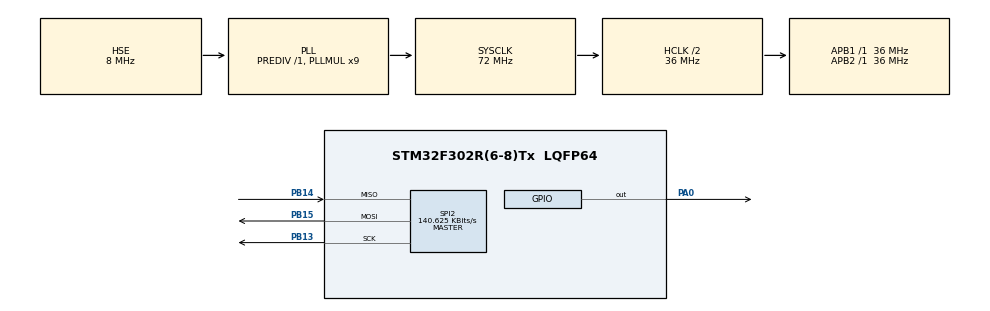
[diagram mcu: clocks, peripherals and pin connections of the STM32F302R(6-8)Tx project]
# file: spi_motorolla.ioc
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Mcu.Family=STM32F3
Mcu.Name=STM32F302R(6-8)Tx
Mcu.Package=LQFP64
NVIC.PriorityGroup=NVIC_PRIORITYGROUP_0
PA0.GPIO_Speed=GPIO_SPEED_FREQ_HIGH
PA0.Signal=GPIO_Output
PA13.GPIO_Label=TMS
PA13.Mode=Serial_Wire
PA13.Signal=SYS_JTMS-SWDIO
PA14.GPIO_Label=TCK
PA14.Mode=Serial_Wire
PA14.Signal=SYS_JTCK-SWCLK
PB13.Mode=Full_Duplex_Master
PB13.Signal=SPI2_SCK
PB14.Mode=Full_Duplex_Master
PB14.Signal=SPI2_MISO
PB15.Mode=Full_Duplex_Master
PB15.Signal=SPI2_MOSI
PC14\ -\ OSC32_IN.Mode=LSE-External-Clock-Source
PC14\ -\ OSC32_IN.Signal=RCC_OSC32_IN
PF0-OSC_IN.Mode=HSE-External-Oscillator
PF0-OSC_IN.Signal=RCC_OSC_IN
PF1-OSC_OUT.Mode=HSE-External-Oscillator
PF1-OSC_OUT.Signal=RCC_OSC_OUT
ProjectManager.HeapSize=0x200
ProjectManager.StackSize=0x400
ProjectManager.TargetToolchain=STM32CubeIDE
RCC.AHBCLKDivider=RCC_SYSCLK_DIV2
RCC.AHBFreq_Value=36000000
RCC.APB1Freq_Value=36000000
RCC.APB1TimFreq_Value=36000000
RCC.APB2Freq_Value=36000000
RCC.APB2TimFreq_Value=36000000
RCC.CortexFreq_Value=36000000
RCC.HCLKFreq_Value=36000000
RCC.HSE_VALUE=8000000
RCC.HSI_VALUE=8000000
RCC.LSE_VALUE=32768
RCC.PLLM=8
RCC.PLLMUL=RCC_PLL_MUL9
RCC.PLLN=336
RCC.PLLP=RCC_PLLP_DIV4
RCC.PLLQ=7
RCC.PLLSourceVirtual=RCC_PLLSOURCE_HSE
RCC.SYSCLKFreq_VALUE=72000000
RCC.SYSCLKSourceVirtual=RCC_SYSCLKSOURCE_PLLCLK
RCC.USBFreq_Value=72000000
SPI2.BaudRatePrescaler=SPI_BAUDRATEPRESCALER_256
SPI2.CalculateBaudRate=140.625 KBits/s
SPI2.DataSize=SPI_DATASIZE_8BIT
SPI2.Direction=SPI_DIRECTION_2LINES
SPI2.Mode=SPI_MODE_MASTER
SPI2.VirtualType=VM_MASTER
board=NUCLEO-F302R8

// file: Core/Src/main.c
/* USER CODE BEGIN Header */
/**
  ******************************************************************************
  * @file           : main.c
  * @brief          : Main program body
  ******************************************************************************
  * @attention
  *
  * Copyright (c) 2026 STMicroelectronics.
  * All rights reserved.
  *
  * This software is licensed under terms that can be found in the LICENSE file
  * in the root directory of this software component.
  * If no LICENSE file comes with this software, it is provided AS-IS.
  *
  ******************************************************************************
  */
/* USER CODE END Header */
#include "main.h"
#include "spi.h"
#include "gpio.h"

/* USER CODE BEGIN PV */

//uint8_t tx_Data[] = {0x11};

uint8_t tx_Data[] = {0x11, 0x22};
uint8_t rx_Data[2];
/* USER CODE END PV */

void SystemClock_Config(void);

int main(void)
{

  /* MCU Configuration--------------------------------------------------------*/

  /* Reset of all peripherals, Initializes the Flash interface and the Systick. */
  HAL_Init();

  /* Configure the system clock */
  SystemClock_Config();

  /* Initialize all configured peripherals */
  MX_GPIO_Init();
  MX_SPI2_Init();

  /* Infinite loop */
  while (1)
  {

    /* USER CODE BEGIN 3 */
	/* HAL_GPIO_WritePin(GPIOA, GPIO_PIN_0, RESET);
	HAL_SPI_Transmit(&hspi2, tx_Data, sizeof(tx_Data), HAL_MAX_DELAY);
	HAL_GPIO_WritePin(GPIOA, GPIO_PIN_0, SET);
	HAL_Delay(1000); */

    HAL_GPIO_WritePin(GPIOA, GPIO_PIN_4, RESET);
    HAL_SPI_TransmitReceive(&hspi2, tx_Data, rx_Data, sizeof(tx_Data), HAL_MAX_DELAY);
	HAL_GPIO_WritePin(GPIOA, GPIO_PIN_4, SET);
	HAL_Delay(1000);
  }
  /* USER CODE END 3 */
}

void SystemClock_Config(void)
{
  RCC_OscInitTypeDef RCC_OscInitStruct = {0};
  RCC_ClkInitTypeDef RCC_ClkInitStruct = {0};

  /** Initializes the RCC Oscillators according to the specified parameters
  * in the RCC_OscInitTypeDef structure.
  */
  RCC_OscInitStruct.OscillatorType = RCC_OSCILLATORTYPE_HSE;
  RCC_OscInitStruct.HSEState = RCC_HSE_ON;
  RCC_OscInitStruct.HSEPredivValue = RCC_HSE_PREDIV_DIV1;
  RCC_OscInitStruct.HSIState = RCC_HSI_ON;
  RCC_OscInitStruct.PLL.PLLState = RCC_PLL_ON;
  RCC_OscInitStruct.PLL.PLLSource = RCC_PLLSOURCE_HSE;
  RCC_OscInitStruct.PLL.PLLMUL = RCC_PLL_MUL9;
  if (HAL_RCC_OscConfig(&RCC_OscInitStruct) != HAL_OK)
  {
    Error_Handler();
  }

  /** Initializes the CPU, AHB and APB buses clocks
  */
  RCC_ClkInitStruct.ClockType = RCC_CLOCKTYPE_HCLK|RCC_CLOCKTYPE_SYSCLK
                              |RCC_CLOCKTYPE_PCLK1|RCC_CLOCKTYPE_PCLK2;
  RCC_ClkInitStruct.SYSCLKSource = RCC_SYSCLKSOURCE_PLLCLK;
  RCC_ClkInitStruct.AHBCLKDivider = RCC_SYSCLK_DIV2;
  RCC_ClkInitStruct.APB1CLKDivider = RCC_HCLK_DIV1;
  RCC_ClkInitStruct.APB2CLKDivider = RCC_HCLK_DIV1;

  if (HAL_RCC_ClockConfig(&RCC_ClkInitStruct, FLASH_LATENCY_1) != HAL_OK)
  {
    Error_Handler();
  }
}

void Error_Handler(void)
{
  __disable_irq();
  while (1)
  {
  }
}
